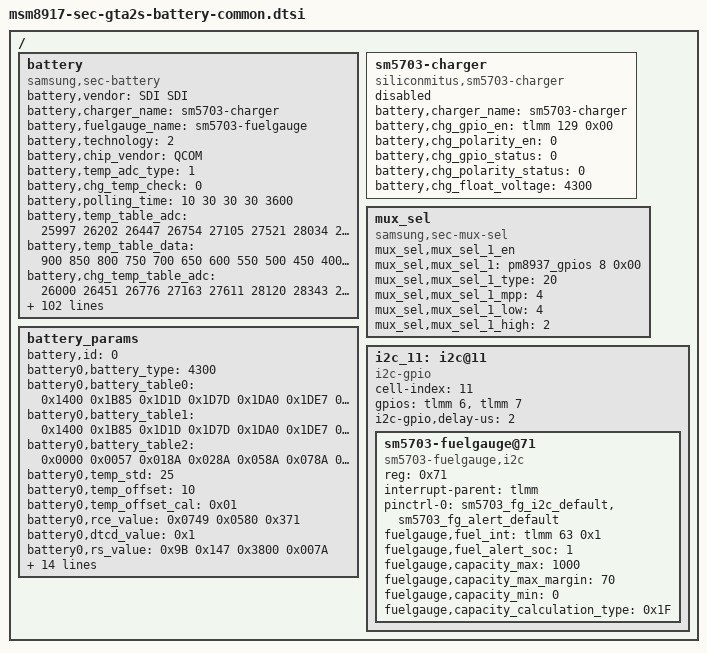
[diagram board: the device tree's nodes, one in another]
/* Copyright (c) 2015, The Linux Foundation. All rights reserved.
 *
 * This program is free software; you can redistribute it and/or modify
 * it under the terms of the GNU General Public License version 2 and
 * only version 2 as published by the Free Software Foundation.
 *
 * This program is distributed in the hope that it will be useful,
 * but WITHOUT ANY WARRANTY; without even the implied warranty of
 * MERCHANTABILITY or FITNESS FOR A PARTICULAR PURPOSE.  See the
 * GNU General Public License for more details.
 */

/ {
	battery {
		status = "okay";
		compatible = "samsung,sec-battery";
		battery,vendor = "SDI SDI";
		battery,charger_name = "sm5703-charger";
		battery,fuelgauge_name = "sm5703-fuelgauge";
		battery,technology = <2>; /* POWER_SUPPLY_TECHNOLOGY_LION */

		battery,chip_vendor = "QCOM";
		battery,temp_adc_type = <1>; /* SEC_BATTERY_ADC_TYPE_AP */

		battery,chg_temp_check = <0>;

		battery,polling_time = <10 30 30 30 3600>;

		battery,temp_table_adc = <25997 26202 26447 26754 27105 27521 28034 28605 29263 30006 30815 31787 32743 33767 34866 35927 36974 37921 38815 39570 40255 40822 41274>;

		battery,temp_table_data = <900 850 800 750 700 650 600 550 500 450 400 350 300 250 200 150 100 50 0 (-50) (-100) (-150) (-200)>;

		battery,chg_temp_table_adc = <26000 26451 26776 27163 27611 28120 28343 28498 28725 28968 29223 29475 29512 29847 30172 31107 32031 32999 34092 35083 36181 37166 38088 38675 39491 40103 40760 41265>;

		battery,chg_temp_table_data = <900 800 750 700 650 600 580 570 550 530 510 500 490 470 450 400 350 300 250 200 150 100 50 0 (-50) (-100) (-150) (-200)>;

		battery,input_current_limit = <1800 500 500 1800 500 900 1000 500 500 1000 820 1800 1800 500 1000 300 700 1000 1000 300 80 500 1800 1000 1800 1000 900 820 820 500 1000 1000 820 820 820 820 820 820 500 1800 1800 500>;
		battery,fast_charging_current = <2100 0 500 2100 500 1200 1000 500 0 1200 1000 2100 2100 0 1300 300 700 1300 1500 300 80 0 2100 1000 2100 1400 1200 1000 1000 0 0 1000 1000 1000 1000 1000 1000 1000 500 500 2100 500>;
		battery,full_check_current_1st = <350 0 350 350 350 350 350 350 0 350 350 350 350 0 350 350 350 350 350 350 350 0 350 350 350 350 350 350 350 0 0 350 350 350 350 350 350 350 350 350>;
		battery,full_check_current_2nd = <250 0 250 250 250 250 250 250 0 250 250 250 250 0 250 250 250 250 250 250 250 0 250 250 250 250 250 250 250 0 0 250 250 250 250 250 250 250 250 250>;

		battery,adc_check_count = <5>;

		battery,cable_check_type = <4>; /* SEC_BATTERY_CABLE_CHECK_PSY */
		battery,cable_source_type = <3>; /* SEC_BATTERY_CABLE_SOURCE_EXTERNAL */
		battery,event_waiting_time = <600>;
		battery,polling_type = <1>; /* SEC_BATTERY_MONITOR_ALARM */
		battery,monitor_initial_count = <3>;

		battery,battery_check_type = <0>; /* SEC_BATTERY_CHECK_NONE */
		battery,check_count = <0>;
		battery,check_adc_max = <1440>;
		battery,check_adc_min = <0>;

		battery,ovp_uvlo_check_type = <3>; /* SEC_BATTERY_OVP_UVLO_CHGPOLLING */

		battery,thermal_source = <2>; /* SEC_BATTERY_THERMAL_SOURCE_ADC */
		battery,chg_thermal_source = <0>;
		battery,mux_channel = <4>;

		battery,temp_check_type = <2>; /* SEC_BATTERY_TEMP_CHECK_TEMP */
		battery,temp_check_count = <1>;
		battery,temp_highlimit_threshold_event = <800>;
		battery,temp_highlimit_recovery_event = <750>;
		battery,temp_high_threshold_event = <500>;
		battery,temp_high_recovery_event = <450>;
		battery,temp_low_threshold_event = <0>;
		battery,temp_low_recovery_event = <50>;
		battery,temp_highlimit_threshold_normal = <800>;
		battery,temp_highlimit_recovery_normal = <750>;
		battery,temp_high_threshold_normal = <500>;
		battery,temp_high_recovery_normal = <450>;
		battery,temp_low_threshold_normal = <0>;
		battery,temp_low_recovery_normal = <50>;
		battery,temp_highlimit_threshold_lpm = <800>;
		battery,temp_highlimit_recovery_lpm = <750>;
		battery,temp_high_threshold_lpm = <500>;
		battery,temp_high_recovery_lpm = <450>;
		battery,temp_low_threshold_lpm = <0>;
		battery,temp_low_recovery_lpm = <50>;
		battery,full_check_type = <2>; /* SEC_BATTERY_FULLCHARGED_FG_CURRENT */
		battery,full_check_type_2nd = <2>; /* SEC_BATTERY_FULLCHARGED_FG_CURRENT */
		battery,full_check_count = <1>;
		battery,chg_gpio_full_check = <0>;
		battery,chg_polarity_full_check = <1>;

		battery,chg_high_temp_1st = <465>;
		battery,chg_high_temp_2nd = <465>;
		battery,chg_high_temp_recovery = <455>;
		battery,chg_charging_limit_current = <1400>;
		battery,chg_charging_limit_current_2nd = <1400>;
		battery,chg_skip_check_capacity = <10>;
		battery,chg_skip_check_time = <600>;

		/* SEC_BATTERY_FULL_CONDITION_SOC |
		   SEC_BATTERY_FULL_CONDITION_NOTIMEFULL |
		   SEC_BATTERY_FULL_CONDITION_VCELL */
		battery,full_condition_type = <13>;
		battery,full_condition_soc = <93>;
		battery,full_condition_vcell = <4200>;

		battery,recharge_check_count = <1>;
		battery,recharge_condition_type = <4>; /* SEC_BATTERY_RECHARGE_CONDITION_VCELL */
		battery,recharge_condition_soc = <98>;
		battery,recharge_condition_vcell = <4230>;

		battery,charging_total_time = <36000>;
		battery,recharging_total_time = <5400>;
		battery,charging_reset_time = <0>;

		battery,standard_curr = <1883>;
		battery,expired_time = <17400>;
		battery,recharging_expired_time = <5400>;

		battery,chg_float_voltage = <4300>;

		battery,swelling_high_temp_block = <410>;
		battery,swelling_high_temp_recov = <390>;
		battery,swelling_low_temp_block_1st = <150>;
		battery,swelling_low_temp_recov_1st = <200>;
		battery,swelling_low_temp_block_2nd = <50>;
		battery,swelling_low_temp_recov_2nd = <100>;

		battery,swelling_low_temp_current = <1050>;  // 0.3C * 3500
		battery,swelling_low_temp_topoff = <250>;  // 0.05C
		battery,swelling_high_temp_current = <1550>;  // 0.45C * 3500
		battery,swelling_high_temp_topoff = <250>;  // 0.05C

		battery,swelling_drop_float_voltage = <4120>;
		battery,swelling_high_rechg_voltage = <3950>;
		battery,swelling_low_rechg_voltage = <3950>;

		battery,siop_event_check_type = <1>;
		battery,siop_call_cv_current = <500>;
		battery,siop_call_cc_current = <500>;

		battery,siop_input_limit_current = <1250>;
		battery,siop_charging_limit_current = <1250>;

		battery,step_charging_type = <0>;
		battery,step_charging_condtion = <4100 4400>;
		battery,step_charging_current = <2100 2100>;

		battery,max_input_voltage = <5000>; /* mV */
		battery,max_input_current = <2100>;  /* mA */

		battery,normal_charging_total_time = <72000>;
		battery,usb_charging_total_time = <72000>;

		/* cycle, chg_float_voltage, recharge_condition_vcell, full_condition_vcell, full_condition_soc */
		battery,age_data = <0   4300 4230 4200 93
				200  4280 4210 4180 92
				250  4260 4190 4160 91
				300  4240 4170 4140 90
				1000 4190 4120 4090 89>;

		battery,cisd_max_voltage_thr = <4350>; /* batttery ovp dettection voltage */

		battery,full_chg_current_margin = <(-10)>;

		battery,pre_afc_input_current = <1800>;
		battery,pre_afc_work_delay = <0>;

		qcom,sec-battery-vadc = <&pm8937_vadc>;
	};

	sm5703-charger {
		status = "disable";
		compatible = "siliconmitus,sm5703-charger";

		/* Charger */
		battery,charger_name = "sm5703-charger";
		battery,chg_gpio_en = <&tlmm 129 0x00>;
		battery,chg_polarity_en = <0>;
		battery,chg_gpio_status = <0>;
		battery,chg_polarity_status = <0>;
		battery,chg_float_voltage = <4300>;
	};

	mux_sel {
		compatible = "samsung,sec-mux-sel";
		mux_sel,mux_sel_1_en;
		mux_sel,mux_sel_1 = <&pm8937_gpios 8 0x00>;
		mux_sel,mux_sel_1_type = <20>; /* BATT_THM_MUX_SEL | AP_THM_MUX_SEL */
		mux_sel,mux_sel_1_mpp = <4>; /* SEC_MPP4_MUX_SEL */
		mux_sel,mux_sel_1_low = <4>; /* SEC_MUX_SEL_AP_THM */
		mux_sel,mux_sel_1_high = <2>; /* SEC_MUX_SEL_BATT_THM */
	};

	battery_params {
		battery,id = <0>; /* -1 means auto, detected by F/G */
		battery0,battery_type = <4300>; /* 4200 4350 4400 */
		battery0,battery_table0 = <0x1400 0x1B85 0x1D1D 0x1D7D 0x1DA0 0x1DE7 0x1E30 0x1E88 0x1ECA 0x1F0A 0x1F7E 0x1FCE 0x2093 0x210D 0x2202 0x2400>;
		battery0,battery_table1 = <0x1400 0x1B85 0x1D1D 0x1D7D 0x1DA0 0x1DE7 0x1E30 0x1E88 0x1ECA 0x1F0A 0x1F7E 0x1FCE 0x2093 0x210D 0x2202 0x2400>;
		battery0,battery_table2 = <0x0000 0x0057 0x018A 0x028A 0x058A 0x078A 0x0B8A 0x118A 0x148A 0x168A 0x188A 0x1B8A 0x1E8A 0x218A 0x25F0 0x2604>;
		battery0,temp_std = <25>;
		battery0,temp_offset = <10>;
		battery0,temp_offset_cal = <0x01>;
		battery0,rce_value = <0x0749 0x0580 0x371>;
		battery0,dtcd_value = <0x1>;
		battery0,rs_value = <0x9B 0x147 0x3800 0x007A>; /*rs mix_factor max min*/
		battery0,vit_period = <0x3506>;
		battery0,mix_value = <0x0403 0x0004>; /*mix_rate init_blank*/
		battery0,topoff_soc = <0x0 0x5>; /*enable soc*/
		battery0,tem_poff = <3400 100 3320 100>;
		battery0,charge_offset_cal = <0x03>;
		battery0,volt_cal = <0x809E>;
		battery0,curr_cal = <0x7585>;
		battery0,ext_temp_cal = <0 10 1 1 1 7 1 1>;
		battery0,v_alarm = <3100>;
		battery0,v_max_table = <0x2202 0x21DA 0x21B1 0x2188 0x2123>;
		battery0,q_max_table = <0x25F0 0x2536 0x247C 0x23C2 0x21F0>;
		battery0,data_ver = <0x04>;
	};

	i2c_11: i2c@11 {
		cell-index = <11>;
		compatible = "i2c-gpio";
		gpios = <&tlmm 6 0	/* sda */
			&tlmm 7 0	/* scl */
			>;
		i2c-gpio,delay-us = <2>;
		#address-cells = <1>;
		#size-cells = <0>;

		sm5703-fuelgauge@71{
			status = "okay";
			compatible = "sm5703-fuelgauge,i2c";
			reg = <0x71>;
			interrupt-parent = <&tlmm>;
			pinctrl-names = "default";
			pinctrl-0 = <&sm5703_fg_i2c_default &sm5703_fg_alert_default>;
			fuelgauge,fuel_int = <&tlmm 63 0x1>;
			fuelgauge,fuel_alert_soc = <1>;
			fuelgauge,capacity_max = <1000>;
			fuelgauge,capacity_max_margin = <70>;
			fuelgauge,capacity_min = <0>;
			fuelgauge,capacity_calculation_type = <0x1F>;
		};
	};
};
